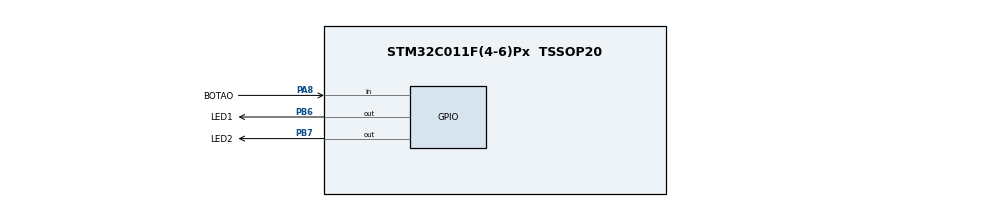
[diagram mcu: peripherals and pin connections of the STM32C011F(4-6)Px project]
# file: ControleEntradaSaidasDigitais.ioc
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Mcu.Family=STM32C0
Mcu.Name=STM32C011F(4-6)Px
Mcu.Package=TSSOP20
PA13.Mode=Serial_Wire
PA13.Signal=DEBUG_SWDIO
PA14-BOOT0.Mode=Serial_Wire
PA14-BOOT0.Signal=DEBUG_SWCLK
PA8.GPIO_Label=BOTAO
PA8.GPIO_PuPd=GPIO_PULLUP
PA8.Signal=GPIO_Input
PB6.GPIO_Label=LED1
PB6.GPIO_Speed=GPIO_SPEED_FREQ_LOW
PB6.Signal=GPIO_Output
PB7.GPIO_Label=LED2
PB7.GPIO_Speed=GPIO_SPEED_FREQ_LOW
PB7.Signal=GPIO_Output
ProjectManager.HeapSize=0x200
ProjectManager.StackSize=0x400
ProjectManager.TargetToolchain=STM32CubeIDE
RCC.ADCFreq_Value=48000000
RCC.AHBFreq_Value=48000000
RCC.CortexFreq_Value=48000000
RCC.EXTERNAL_CLOCK_VALUE=12288000
RCC.HCLKFreq_Value=48000000
RCC.HSE_VALUE=8000000
RCC.HSISYSCLKDivider=RCC_HSI_DIV1
RCC.HSI_VALUE=48000000
RCC.LSE_VALUE=32768
RCC.SYSCLKFreq_VALUE=48000000
board=custom

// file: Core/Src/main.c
/* USER CODE BEGIN Header */
/**
  ******************************************************************************
  * @file           : main.c
  * @brief          : Main program body
  ******************************************************************************
  * @attention
  *
  * Copyright (c) 2024 STMicroelectronics.
  * All rights reserved.
  *
  * This software is licensed under terms that can be found in the LICENSE file
  * in the root directory of this software component.
  * If no LICENSE file comes with this software, it is provided AS-IS.
  *
  ******************************************************************************
  */
/* USER CODE END Header */
#include "main.h"

void SystemClock_Config(void);
static void MX_GPIO_Init(void);

int main(void)
{

  /* MCU Configuration--------------------------------------------------------*/

  /* Reset of all peripherals, Initializes the Flash interface and the Systick. */
  HAL_Init();

  /* Configure the system clock */
  SystemClock_Config();

  /* Initialize all configured peripherals */
  MX_GPIO_Init();

  /* Infinite loop */
  while (1)
    {

    /* USER CODE BEGIN 3 */
	  /* EXEMPLO 1 */
	  if(HAL_GPIO_ReadPin(BOTAO_GPIO_Port, BOTAO_Pin)==0){
		  HAL_GPIO_TogglePin(GPIOB, LED1_Pin|LED2_Pin);
	  	  HAL_Delay(1000);
	  }
	 /* EXEMPLO 2
	 if(HAL_GPIO_ReadPin(BOTAO_GPIO_Port, BOTAO_Pin)==0){
		 HAL_GPIO_WritePin(GPIOB, LED1_Pin, GPIO_PIN_SET);
	 	 HAL_GPIO_WritePin(GPIOB, LED2_Pin, GPIO_PIN_RESET);
	 }else{
	 	 HAL_GPIO_WritePin(GPIOB, LED2_Pin, GPIO_PIN_SET);
	 	 HAL_GPIO_WritePin(GPIOB, LED1_Pin, GPIO_PIN_RESET);
	 }*/

    }
  /* USER CODE END 3 */
}

void SystemClock_Config(void)
{
  RCC_OscInitTypeDef RCC_OscInitStruct = {0};
  RCC_ClkInitTypeDef RCC_ClkInitStruct = {0};

  /** Initializes the RCC Oscillators according to the specified parameters
  * in the RCC_OscInitTypeDef structure.
  */
  RCC_OscInitStruct.OscillatorType = RCC_OSCILLATORTYPE_HSI;
  RCC_OscInitStruct.HSIState = RCC_HSI_ON;
  RCC_OscInitStruct.HSIDiv = RCC_HSI_DIV1;
  RCC_OscInitStruct.HSICalibrationValue = RCC_HSICALIBRATION_DEFAULT;
  if (HAL_RCC_OscConfig(&RCC_OscInitStruct) != HAL_OK)
  {
    Error_Handler();
  }

  /** Initializes the CPU, AHB and APB buses clocks
  */
  RCC_ClkInitStruct.ClockType = RCC_CLOCKTYPE_HCLK|RCC_CLOCKTYPE_SYSCLK
                              |RCC_CLOCKTYPE_PCLK1;
  RCC_ClkInitStruct.SYSCLKSource = RCC_SYSCLKSOURCE_HSI;
  RCC_ClkInitStruct.SYSCLKDivider = RCC_SYSCLK_DIV1;
  RCC_ClkInitStruct.AHBCLKDivider = RCC_HCLK_DIV1;
  RCC_ClkInitStruct.APB1CLKDivider = RCC_APB1_DIV1;

  if (HAL_RCC_ClockConfig(&RCC_ClkInitStruct, FLASH_LATENCY_1) != HAL_OK)
  {
    Error_Handler();
  }
}

static void MX_GPIO_Init(void)
{
  GPIO_InitTypeDef GPIO_InitStruct = {0};

  /* GPIO Ports Clock Enable */
  __HAL_RCC_GPIOB_CLK_ENABLE();
  __HAL_RCC_GPIOA_CLK_ENABLE();

  /*Configure GPIO pin Output Level */
  HAL_GPIO_WritePin(GPIOB, LED2_Pin|LED1_Pin, GPIO_PIN_RESET);

  /*Configure GPIO pins : LED2_Pin LED1_Pin */
  GPIO_InitStruct.Pin = LED2_Pin|LED1_Pin;
  GPIO_InitStruct.Mode = GPIO_MODE_OUTPUT_PP;
  GPIO_InitStruct.Pull = GPIO_NOPULL;
  GPIO_InitStruct.Speed = GPIO_SPEED_FREQ_LOW;
  HAL_GPIO_Init(GPIOB, &GPIO_InitStruct);

  /*Configure GPIO pin : BOTAO_Pin */
  GPIO_InitStruct.Pin = BOTAO_Pin;
  GPIO_InitStruct.Mode = GPIO_MODE_INPUT;
  GPIO_InitStruct.Pull = GPIO_PULLUP;
  HAL_GPIO_Init(BOTAO_GPIO_Port, &GPIO_InitStruct);

}

void Error_Handler(void)
{
  __disable_irq();
  while (1)
  {
  }
}
